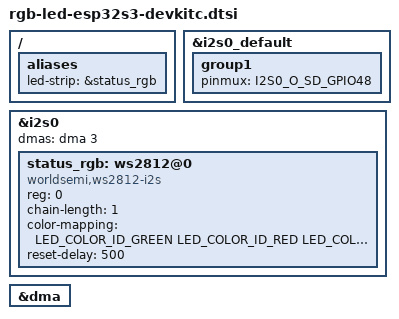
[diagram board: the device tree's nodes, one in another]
/* SPDX-License-Identifier: Apache-2.0
 *
 * Status LED: the WS2812 addressable RGB LED of the ESP32-S3-DevKitC-1, driven
 * by the I2S0 peripheral as in Zephyr's led_strip sample. It is on GPIO48 on
 * the board's v1.0 and on GPIO38 on v1.1. lib/common/status_led.c uses the
 * `led-strip` alias when the board has no plain `led0`. (The board's red LED is
 * the power LED and cannot be driven.)
 */
#include <zephyr/dt-bindings/led/led.h>

/ {
	aliases {
		led-strip = &status_rgb;
	};
};

&i2s0_default {
	group1 {
		pinmux = <I2S0_O_SD_GPIO48>;
	};
};

&i2s0 {
	status = "okay";
	dmas = <&dma 3>;
	dma-names = "tx";

	status_rgb: ws2812@0 {
		compatible = "worldsemi,ws2812-i2s";
		reg = <0>;
		chain-length = <1>;
		color-mapping = <LED_COLOR_ID_GREEN
				 LED_COLOR_ID_RED
				 LED_COLOR_ID_BLUE>;
		reset-delay = <500>;
	};
};

&dma {
	status = "okay";
};
